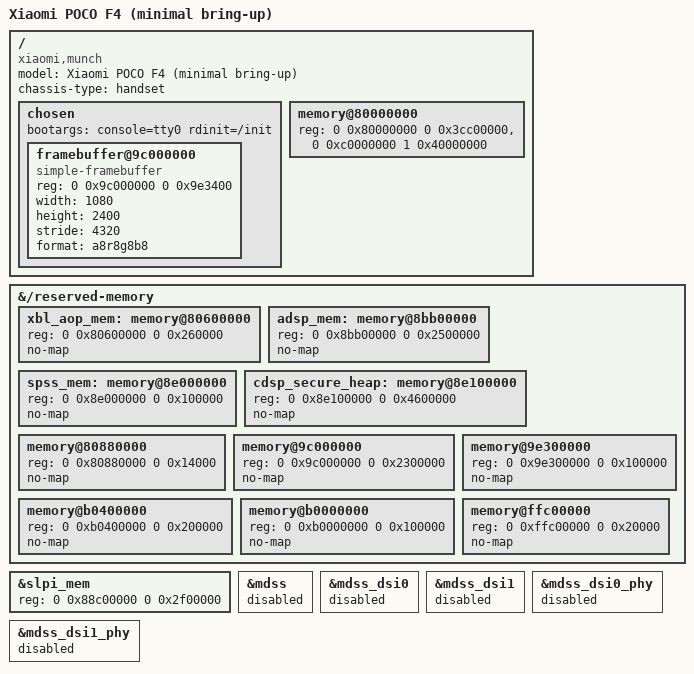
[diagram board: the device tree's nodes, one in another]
// SPDX-License-Identifier: BSD-3-Clause
/dts-v1/;
#include "sm8250.dtsi"
/ {
 model = "Xiaomi POCO F4 (minimal bring-up)";
 compatible = "xiaomi,munch", "qcom,sm8250";
 chassis-type = "handset";
 chosen {
  #address-cells = <2>;
  #size-cells = <2>;
  ranges;
  bootargs = "console=tty0 rdinit=/init";
  framebuffer@9c000000 {
   compatible = "simple-framebuffer";
   reg = <0 0x9c000000 0 0x9e3400>;
   width = <1080>;
   height = <2400>;
   stride = <4320>;
   format = "a8r8g8b8";
  };
 };
 memory@80000000 {
  device_type = "memory";
  reg = <0 0x80000000 0 0x3cc00000>, <0 0xc0000000 1 0x40000000>;
 };
};
/* Source: old full.dtb and munch DT agree on these firmware carve-outs.
 * Android provenance still needs independent confirmation on this exact handset.
 * Keep reservations even for firmware devices we do not enable.
 */
&{/reserved-memory} {
 /delete-node/ memory@80700000;
 /delete-node/ memory@8a100000;
 /delete-node/ memory@8be00000;
 /delete-node/ memory@8bf00000;
 /* CPU domains, apps_rsc and the inherited dynamic heap remain intact. */
 xbl_aop_mem: memory@80600000 { reg = <0 0x80600000 0 0x260000>; no-map; };
 adsp_mem: memory@8bb00000 { reg = <0 0x8bb00000 0 0x2500000>; no-map; };
 spss_mem: memory@8e000000 { reg = <0 0x8e000000 0 0x100000>; no-map; };
 cdsp_secure_heap: memory@8e100000 { reg = <0 0x8e100000 0 0x4600000>; no-map; };
 memory@80880000 { reg = <0 0x80880000 0 0x14000>; no-map; };
 /* Contiguous splash + dfps reservations; do not lend either to Linux. */
 memory@9c000000 { reg = <0 0x9c000000 0 0x2300000>; no-map; };
 memory@9e300000 { reg = <0 0x9e300000 0 0x100000>; no-map; };
 memory@b0400000 { reg = <0 0xb0400000 0 0x200000>; no-map; };
 /* Reserve old ramoops region, but do not assume an Android-compatible layout. */
 memory@b0000000 { reg = <0 0xb0000000 0 0x100000>; no-map; };
 /* Present only in the old munch DTS: retain conservatively pending verification. */
 memory@ffc00000 { reg = <0 0xffc00000 0 0x20000>; no-map; };
};
&slpi_mem { reg = <0 0x88c00000 0 0x2f00000>; };
/* Bootloader owns display pipeline. FB_SIMPLE only writes splash memory.
 * dispcc/videocc nodes are deliberately unchanged; driver policy is in config.
 */
&mdss { status = "disabled"; };
&mdss_dsi0 { status = "disabled"; };
&mdss_dsi1 { status = "disabled"; };
&mdss_dsi0_phy { status = "disabled"; };
&mdss_dsi1_phy { status = "disabled"; };
